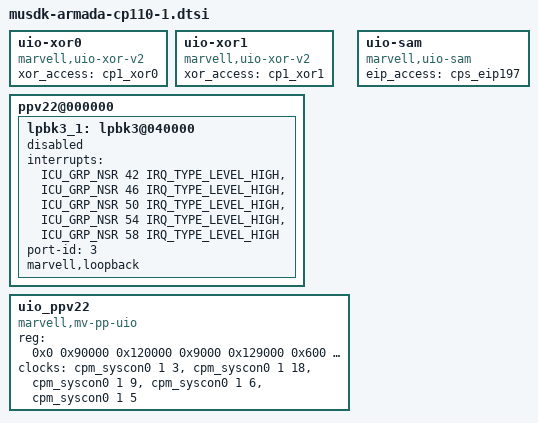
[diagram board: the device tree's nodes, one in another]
/****************************************************************************
* This program is free software: you can redistribute it and/or modify it
* under the terms of the GNU General Public License as published by the Free
* Software Foundation, either version 2 of the License, or any later version.
*
* This program is distributed in the hope that it will be useful,
* but WITHOUT ANY WARRANTY; without even the implied warranty of
* MERCHANTABILITY or FITNESS FOR A PARTICULAR PURPOSE.  See the
* GNU General Public License for more details.
*
* You should have received a copy of the GNU General Public License
* along with this program.  If not, see <http://www.gnu.org/licenses/>.
* ***************************************************************************
*/

/*
 * Generic Device Tree describing Marvell Armada CP-110 device
 */

uio-xor0 {
	compatible = "marvell,uio-xor-v2";
	xor_access = <&cp1_xor0>;
	status = "okay";
};

uio-xor1 {
	compatible = "marvell,uio-xor-v2";
	xor_access = <&cp1_xor1>;
	status = "okay";
};

ppv22@000000 {
	lpbk3_1: lpbk3@040000 {
		interrupts = <ICU_GRP_NSR 42 IRQ_TYPE_LEVEL_HIGH>, /* TX CPU#0 Interrupt */
			     <ICU_GRP_NSR 46 IRQ_TYPE_LEVEL_HIGH>, /* TX CPU#1 Interrupt */
			     <ICU_GRP_NSR 50 IRQ_TYPE_LEVEL_HIGH>, /* TX CPU#2 Interrupt */
			     <ICU_GRP_NSR 54 IRQ_TYPE_LEVEL_HIGH>, /* TX CPU#3 Interrupt */
			     <ICU_GRP_NSR 58 IRQ_TYPE_LEVEL_HIGH>; /* RX Shared Interrupt */
		port-id = <3>; /* pp2_port_id */
		marvell,loopback;
		status = "disabled";
	};
};

uio_ppv22 {
	compatible = "marvell,mv-pp-uio";
	reg = <0x0 0x90000 0x120000 0x9000 0x129000 0x600 0x12a200 0x200 0x130000 0x6000 0x441000 0x1000>;
	reg-names = "pp", "serdes", "xmib", "smi", "mspg", "rfu1";
	clocks = <&cpm_syscon0 1 3>, <&cpm_syscon0 1 18>, <&cpm_syscon0 1 9>,
		<&cpm_syscon0 1 6>, <&cpm_syscon0 1 5>;
	clock-names = "pp_clk", "gop_core_clk", "gop_clk", "mg_core_clk", "mg_clk";
	status = "okay";
/* Note: Ports are currently not read by musdk.
	eth0@010000 {
		interrupts = <0x0 0x25 0x4 0x0 0x29 0x4 0x0 0x2d 0x4 0x0 0x31 0x4 0x0 0x35 0x4>;
		port-id = <0x0>;
		emac-data = <0x24>;
		status = "disabled";
	};

	eth1@020000 {
		interrupts = <0x0 0x26 0x4 0x0 0x2a 0x4 0x0 0x2e 0x4 0x0 0x32 0x4 0x0 0x36 0x4>;
		port-id = <0x1>;
		emac-data = <0x25>;
		status = "disabled";
	};
*/
};

uio-sam {
	compatible = "marvell,uio-sam";
	eip_access = <&cps_eip197>;
	status = "okay";
};
